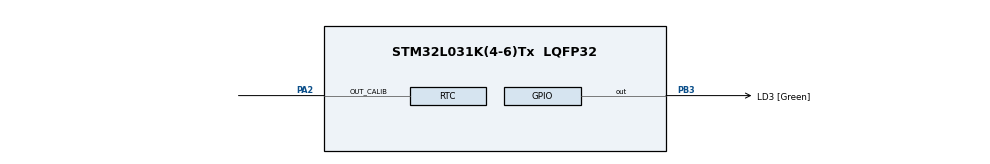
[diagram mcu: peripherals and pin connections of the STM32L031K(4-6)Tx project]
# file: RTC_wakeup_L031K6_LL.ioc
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Mcu.Family=STM32L0
Mcu.Name=STM32L031K(4-6)Tx
Mcu.Package=LQFP32
NVIC.RTC_IRQn=true\:0\:0\:false\:false\:true\:true\:true\:true
PA13.GPIO_Label=TMS
PA13.Mode=Serial_Wire
PA13.Signal=SYS_SWDIO
PA14.GPIO_Label=TCK
PA14.Mode=Serial_Wire
PA14.Signal=SYS_SWCLK
PA2.Mode=Calibration_1Hz
PA2.Signal=RTC_OUT_CALIB
PB3.GPIO_Label=LD3 [Green]
PB3.Signal=GPIO_Output
PC14-OSC32_IN.Mode=LSE-External-Oscillator
PC14-OSC32_IN.Signal=RCC_OSC32_IN
PC15-OSC32_OUT.Mode=LSE-External-Oscillator
PC15-OSC32_OUT.Signal=RCC_OSC32_OUT
ProjectManager.HeapSize=0x200
ProjectManager.StackSize=0x400
ProjectManager.TargetToolchain=STM32CubeIDE
RCC.AHBFreq_Value=32000000
RCC.APB1Freq_Value=32000000
RCC.APB1TimFreq_Value=32000000
RCC.APB2Freq_Value=32000000
RCC.APB2TimFreq_Value=32000000
RCC.HCLKFreq_Value=32000000
RCC.HSE_VALUE=8000000
RCC.HSI16_VALUE=16000000
RCC.HSI48_VALUE=48000000
RCC.HSI_VALUE=16000000
RCC.MSI_VALUE=2097000
RCC.PLLMUL=RCC_PLLMUL_4
RCC.RTCClockSelection=RCC_RTCCLKSOURCE_LSE
RCC.RTCClockSelectionVirtual=RCC_RTCCLKSOURCE_LSE
RCC.SYSCLKFreq_VALUE=32000000
RCC.SYSCLKSource=RCC_SYSCLKSOURCE_PLLCLK
RCC.VCOOutputFreq_Value=64000000
RTC.WakeUpClock-WakeUp=RTC_WAKEUPCLOCK_CK_SPRE_16BITS
RTC.WakeUpCounter-WakeUp=2
VP_RTC_VS_RTC_Activate.Mode=RTC_Enabled
VP_RTC_VS_RTC_WakeUp_intern.Mode=WakeUp
board=NUCLEO-L031K6

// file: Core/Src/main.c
/* USER CODE BEGIN Header */
/**
  ******************************************************************************
  * @file           : main.c
  * @brief          : Main program body
  ******************************************************************************
  * @attention
  *
  * Copyright (c) 2024 STMicroelectronics.
  * All rights reserved.
  *
  * This software is licensed under terms that can be found in the LICENSE file
  * in the root directory of this software component.
  * If no LICENSE file comes with this software, it is provided AS-IS.
  *
  ******************************************************************************
  */
/* USER CODE END Header */
#include "main.h"
#include "rtc.h"
#include "gpio.h"

void SystemClock_Config(void);

int main(void)
{

  /* MCU Configuration--------------------------------------------------------*/

  /* Reset of all peripherals, Initializes the Flash interface and the Systick. */
  LL_APB2_GRP1_EnableClock(LL_APB2_GRP1_PERIPH_SYSCFG);
  LL_APB1_GRP1_EnableClock(LL_APB1_GRP1_PERIPH_PWR);

  /* Configure the system clock */
  SystemClock_Config();

  /* Initialize all configured peripherals */
  MX_GPIO_Init();
  MX_RTC_Init();
  /* USER CODE BEGIN 2 */
  LL_EXTI_EnableIT_0_31(LL_EXTI_LINE_20);  			// Enable interrupt for EXTI line 20
  LL_EXTI_EnableRisingTrig_0_31(LL_EXTI_LINE_20);  	// Trigger on rising edge for line 20

  LL_RTC_DisableWriteProtection(RTC);
  //LL_RTC_EnableInitMode(RTC);
  LL_RTC_WAKEUP_Disable(RTC);
  while(!LL_RTC_IsActiveFlag_WUTW(RTC));
  LL_RTC_WAKEUP_SetAutoReload(RTC, 0);
  LL_RTC_WAKEUP_SetClock(RTC, LL_RTC_WAKEUPCLOCK_CKSPRE);
  LL_RTC_EnableIT_WUT(RTC);
  LL_RTC_WAKEUP_Enable(RTC);
  LL_RTC_ClearFlag_WUT(RTC);
  //LL_RTC_DisableInitMode(RTC);
  LL_RTC_EnableWriteProtection(RTC);

  /* USER CODE END 2 */

  /* Infinite loop */
  while (1)
  {

  }
}

void SystemClock_Config(void)
{
  LL_FLASH_SetLatency(LL_FLASH_LATENCY_1);
  while(LL_FLASH_GetLatency()!= LL_FLASH_LATENCY_1)
  {
  }
  LL_PWR_SetRegulVoltageScaling(LL_PWR_REGU_VOLTAGE_SCALE1);
  while (LL_PWR_IsActiveFlag_VOS() != 0)
  {
  }
  LL_RCC_HSI_Enable();

   /* Wait till HSI is ready */
  while(LL_RCC_HSI_IsReady() != 1)
  {

  }
  LL_RCC_HSI_SetCalibTrimming(16);
  LL_PWR_EnableBkUpAccess();
  if(LL_RCC_GetRTCClockSource() != LL_RCC_RTC_CLKSOURCE_LSE)
  {
    LL_RCC_ForceBackupDomainReset();
    LL_RCC_ReleaseBackupDomainReset();
  }
  LL_RCC_LSE_SetDriveCapability(LL_RCC_LSEDRIVE_LOW);
  LL_RCC_LSE_Enable();

   /* Wait till LSE is ready */
  while(LL_RCC_LSE_IsReady() != 1)
  {

  }
  if(LL_RCC_GetRTCClockSource() != LL_RCC_RTC_CLKSOURCE_LSE)
  {
    LL_RCC_SetRTCClockSource(LL_RCC_RTC_CLKSOURCE_LSE);
  }
  LL_RCC_EnableRTC();
  LL_RCC_PLL_ConfigDomain_SYS(LL_RCC_PLLSOURCE_HSI, LL_RCC_PLL_MUL_4, LL_RCC_PLL_DIV_2);
  LL_RCC_PLL_Enable();

   /* Wait till PLL is ready */
  while(LL_RCC_PLL_IsReady() != 1)
  {

  }
  LL_RCC_SetAHBPrescaler(LL_RCC_SYSCLK_DIV_1);
  LL_RCC_SetAPB1Prescaler(LL_RCC_APB1_DIV_1);
  LL_RCC_SetAPB2Prescaler(LL_RCC_APB2_DIV_1);
  LL_RCC_SetSysClkSource(LL_RCC_SYS_CLKSOURCE_PLL);

   /* Wait till System clock is ready */
  while(LL_RCC_GetSysClkSource() != LL_RCC_SYS_CLKSOURCE_STATUS_PLL)
  {

  }

  LL_Init1msTick(32000000);

  LL_SetSystemCoreClock(32000000);
}

void Error_Handler(void)
{
  __disable_irq();
  while (1)
  {
  }
}
